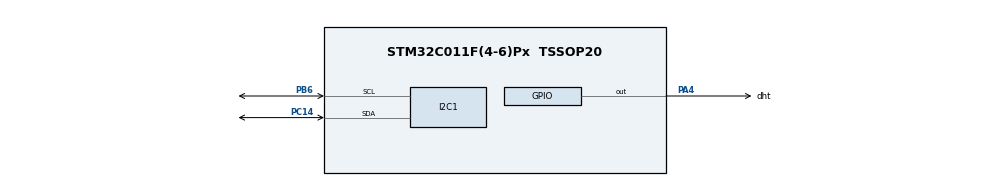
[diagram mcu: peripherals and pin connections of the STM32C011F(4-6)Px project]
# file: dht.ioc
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I2C1.Timing=0x20303E5D
Mcu.Family=STM32C0
Mcu.Name=STM32C011F(4-6)Px
Mcu.Package=TSSOP20
PA13.Mode=Serial_Wire
PA13.Signal=DEBUG_SWDIO
PA14-BOOT0.Mode=Serial_Wire
PA14-BOOT0.Signal=DEBUG_SWCLK
PA4.GPIO_Label=dht
PA4.GPIO_Speed=GPIO_SPEED_FREQ_VERY_HIGH
PA4.PinState=GPIO_PIN_SET
PA4.Signal=GPIO_Output
PB6.Mode=I2C
PB6.Signal=I2C1_SCL
PC14-OSCX_IN\ (PC14).Mode=I2C
PC14-OSCX_IN\ (PC14).Signal=I2C1_SDA
ProjectManager.HeapSize=0x200
ProjectManager.StackSize=0x400
ProjectManager.TargetToolchain=STM32CubeIDE
RCC.ADCFreq_Value=48000000
RCC.AHBFreq_Value=48000000
RCC.CortexFreq_Value=48000000
RCC.EXTERNAL_CLOCK_VALUE=12288000
RCC.HCLKFreq_Value=48000000
RCC.HSE_VALUE=8000000
RCC.HSISYSCLKDivider=RCC_HSI_DIV1
RCC.HSI_VALUE=48000000
RCC.LSE_VALUE=32768
RCC.SYSCLKFreq_VALUE=48000000
TIM3.Period=\ 65535
TIM3.Prescaler=48-1
VP_TIM3_VS_ClockSourceINT.Mode=Internal
board=custom

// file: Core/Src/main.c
/* USER CODE BEGIN Header */
/**
  ******************************************************************************
  * @file           : main.c
  * @brief          : Main program body
  ******************************************************************************
  * @attention
  *
  * Copyright (c) 2024 STMicroelectronics.
  * All rights reserved.
  *
  * This software is licensed under terms that can be found in the LICENSE file
  * in the root directory of this software component.
  * If no LICENSE file comes with this software, it is provided AS-IS.
  *
  ******************************************************************************
  */
/* USER CODE END Header */
#include "main.h"

/* USER CODE BEGIN Includes */
#include "stdio.h"
#include "string.h"
#include "ssd1306.h"
#include "ssd1306_fonts.h"
/* USER CODE END Includes */

I2C_HandleTypeDef hi2c1;

TIM_HandleTypeDef htim3;

/* USER CODE BEGIN PV */
uint16_t temperatura, umidade;
/* USER CODE END PV */

void SystemClock_Config(void);
static void MX_GPIO_Init(void);
static void MX_I2C1_Init(void);
static void MX_TIM3_Init(void);
/* USER CODE BEGIN PFP */
void dht11(uint16_t *temperatura, uint16_t *umidade);
void Display_Data(uint16_t *temperatura, uint16_t *umidade);
/* USER CODE END PFP */

/* USER CODE BEGIN 0 */

void dht11(uint16_t *temperatura, uint16_t *umidade)
{
	//Variáveis para execução de cálculos da função.
	uint16_t tempcalc, umidcalc;

	//Configurações para seleção da direção do Pino 'dht11' como saída digital:
	GPIO_InitTypeDef GPIO_InitStruct = {0};
	GPIO_InitStruct.Pin = dht_Pin;
	GPIO_InitStruct.Mode = GPIO_MODE_OUTPUT_PP;
	GPIO_InitStruct.Pull = GPIO_NOPULL;
	GPIO_InitStruct.Speed = GPIO_SPEED_FREQ_VERY_HIGH;
	HAL_GPIO_Init(dht_GPIO_Port, &GPIO_InitStruct);

	//Sinal em nivel lógico 0 - Conforme Datasheet.
	HAL_GPIO_WritePin(dht_GPIO_Port, dht_Pin, GPIO_PIN_RESET);

	//Tempo mínimo de 18ms - Conforme Datasheet.
	HAL_Delay(20); //Configura para 20ms

	//Sinal em nivel lógico 1 - Conforme Datasheet.
	HAL_GPIO_WritePin(dht_GPIO_Port, dht_Pin, GPIO_PIN_SET);

	//Configurações para seleção da direção do Pino 'dht11' como entrada digital:
	GPIO_InitStruct.Pin = dht_Pin;
	GPIO_InitStruct.Mode = GPIO_MODE_INPUT;
	GPIO_InitStruct.Pull = GPIO_NOPULL;
	GPIO_InitStruct.Speed = GPIO_SPEED_FREQ_VERY_HIGH;
	HAL_GPIO_Init(dht_GPIO_Port, &GPIO_InitStruct);

	//Lógica Principal:
	//Seta contador Timer 3 para 0.
	__HAL_TIM_SET_COUNTER(&htim3, 0);

	//Variáveis Auxiliares.
	uint16_t ler[2];
	uint16_t dados[42];
	uint8_t bits[40];
	uint16_t temph = 0;
	uint16_t umidh = 0;

	//Lógica Para Captura do Tempo Alto dos Dados.
	for(int i = 0; i < 42; i++)
	{
	    while(HAL_GPIO_ReadPin(dht_GPIO_Port, dht_Pin) == GPIO_PIN_RESET);
	    ler[0] = __HAL_TIM_GET_COUNTER(&htim3);
		while(HAL_GPIO_ReadPin(dht_GPIO_Port, dht_Pin) == GPIO_PIN_SET);
		ler[1] = __HAL_TIM_GET_COUNTER(&htim3);
		dados[i] = ler[1] - ler[0];
	}

	//Definindo bits conforme tempos do datasheet.
	for(int i = 0; i < 40; i++)
	{
	    if((dados[i+2] >=20) && (dados[i+2] <=32))
	    {
		    bits[i] = 0;
	    }
	    else if((dados[i+2] >=65) && (dados[i+2] <=75))
	    {
		    bits[i] = 1;
	    }
	}

	//Cálculo da temperatura e umidade determinado pelos bits.
	for(int i = 0; i < 8; i++)
	{
	    temph += bits[i+16] << (7 - i);
	    umidh += bits[i] << (7 - i);
	}

	//Atribuição dos valores calculados nas variáveis
	tempcalc = temph;
	umidcalc = umidh;
	*temperatura = tempcalc;
	*umidade = umidcalc;
}

void Display_Data(uint16_t *temperatura, uint16_t *umidade) {
	char temp_str[16];
	char hum_str[16];

	// Formatando as strings de temperatura e umidade manualmente
	sprintf(temp_str, "Temp: %dC", (int)*temperatura);
	sprintf(hum_str, "Umid: %d%%", (int)*umidade);

	// Limpar o display
	ssd1306_Fill(Black);

	// Definir o cursor e escrever a string de temperatura
	ssd1306_SetCursor(4, 4);
	ssd1306_WriteString(temp_str, Font_11x18, White);

	// Definir o cursor e escrever a string de umidade
	ssd1306_SetCursor(4, 24);
	ssd1306_WriteString(hum_str, Font_11x18, White);

	// Atualizar o display
	ssd1306_UpdateScreen();
}

/* USER CODE END 0 */

int main(void)
{

  /* MCU Configuration--------------------------------------------------------*/

  /* Reset of all peripherals, Initializes the Flash interface and the Systick. */
  HAL_Init();

  /* Configure the system clock */
  SystemClock_Config();

  /* Initialize all configured peripherals */
  MX_GPIO_Init();
  MX_I2C1_Init();
  MX_TIM3_Init();
  /* USER CODE BEGIN 2 */
  HAL_TIM_Base_Start(&htim3); //Inicializa Timer 3 -> '1us'
  ssd1306_Init();
  /* USER CODE END 2 */

  /* Infinite loop */
  while (1)
  {

    /* USER CODE BEGIN 3 */
	dht11(&temperatura, &umidade);
	Display_Data(&temperatura, &umidade);
	HAL_Delay(5000); // Aguarda 5 segundos antes de fazer uma nova leitura
  }
  /* USER CODE END 3 */
}

void SystemClock_Config(void)
{
  RCC_OscInitTypeDef RCC_OscInitStruct = {0};
  RCC_ClkInitTypeDef RCC_ClkInitStruct = {0};

  /** Initializes the RCC Oscillators according to the specified parameters
  * in the RCC_OscInitTypeDef structure.
  */
  RCC_OscInitStruct.OscillatorType = RCC_OSCILLATORTYPE_HSI;
  RCC_OscInitStruct.HSIState = RCC_HSI_ON;
  RCC_OscInitStruct.HSIDiv = RCC_HSI_DIV1;
  RCC_OscInitStruct.HSICalibrationValue = RCC_HSICALIBRATION_DEFAULT;
  if (HAL_RCC_OscConfig(&RCC_OscInitStruct) != HAL_OK)
  {
    Error_Handler();
  }

  /** Initializes the CPU, AHB and APB buses clocks
  */
  RCC_ClkInitStruct.ClockType = RCC_CLOCKTYPE_HCLK|RCC_CLOCKTYPE_SYSCLK
                              |RCC_CLOCKTYPE_PCLK1;
  RCC_ClkInitStruct.SYSCLKSource = RCC_SYSCLKSOURCE_HSI;
  RCC_ClkInitStruct.SYSCLKDivider = RCC_SYSCLK_DIV1;
  RCC_ClkInitStruct.AHBCLKDivider = RCC_HCLK_DIV1;
  RCC_ClkInitStruct.APB1CLKDivider = RCC_APB1_DIV1;

  if (HAL_RCC_ClockConfig(&RCC_ClkInitStruct, FLASH_LATENCY_1) != HAL_OK)
  {
    Error_Handler();
  }
}

static void MX_I2C1_Init(void)
{

  hi2c1.Instance = I2C1;
  hi2c1.Init.Timing = 0x20303E5D;
  hi2c1.Init.OwnAddress1 = 0;
  hi2c1.Init.AddressingMode = I2C_ADDRESSINGMODE_7BIT;
  hi2c1.Init.DualAddressMode = I2C_DUALADDRESS_DISABLE;
  hi2c1.Init.OwnAddress2 = 0;
  hi2c1.Init.OwnAddress2Masks = I2C_OA2_NOMASK;
  hi2c1.Init.GeneralCallMode = I2C_GENERALCALL_DISABLE;
  hi2c1.Init.NoStretchMode = I2C_NOSTRETCH_DISABLE;
  if (HAL_I2C_Init(&hi2c1) != HAL_OK)
  {
    Error_Handler();
  }

  /** Configure Analogue filter
  */
  if (HAL_I2CEx_ConfigAnalogFilter(&hi2c1, I2C_ANALOGFILTER_ENABLE) != HAL_OK)
  {
    Error_Handler();
  }

  /** Configure Digital filter
  */
  if (HAL_I2CEx_ConfigDigitalFilter(&hi2c1, 0) != HAL_OK)
  {
    Error_Handler();
  }

}

static void MX_TIM3_Init(void)
{

  TIM_ClockConfigTypeDef sClockSourceConfig = {0};
  TIM_MasterConfigTypeDef sMasterConfig = {0};

  htim3.Instance = TIM3;
  htim3.Init.Prescaler = 48-1;
  htim3.Init.CounterMode = TIM_COUNTERMODE_UP;
  htim3.Init.Period = 65535;
  htim3.Init.ClockDivision = TIM_CLOCKDIVISION_DIV1;
  htim3.Init.AutoReloadPreload = TIM_AUTORELOAD_PRELOAD_DISABLE;
  if (HAL_TIM_Base_Init(&htim3) != HAL_OK)
  {
    Error_Handler();
  }
  sClockSourceConfig.ClockSource = TIM_CLOCKSOURCE_INTERNAL;
  if (HAL_TIM_ConfigClockSource(&htim3, &sClockSourceConfig) != HAL_OK)
  {
    Error_Handler();
  }
  sMasterConfig.MasterOutputTrigger = TIM_TRGO_RESET;
  sMasterConfig.MasterSlaveMode = TIM_MASTERSLAVEMODE_DISABLE;
  if (HAL_TIMEx_MasterConfigSynchronization(&htim3, &sMasterConfig) != HAL_OK)
  {
    Error_Handler();
  }

}

static void MX_GPIO_Init(void)
{
  GPIO_InitTypeDef GPIO_InitStruct = {0};

  /* GPIO Ports Clock Enable */
  __HAL_RCC_GPIOC_CLK_ENABLE();
  __HAL_RCC_GPIOA_CLK_ENABLE();
  __HAL_RCC_GPIOB_CLK_ENABLE();

  /*Configure GPIO pin Output Level */
  HAL_GPIO_WritePin(dht_GPIO_Port, dht_Pin, GPIO_PIN_SET);

  /*Configure GPIO pin : dht_Pin */
  GPIO_InitStruct.Pin = dht_Pin;
  GPIO_InitStruct.Mode = GPIO_MODE_OUTPUT_PP;
  GPIO_InitStruct.Pull = GPIO_NOPULL;
  GPIO_InitStruct.Speed = GPIO_SPEED_FREQ_VERY_HIGH;
  HAL_GPIO_Init(dht_GPIO_Port, &GPIO_InitStruct);

}

void Error_Handler(void)
{
  __disable_irq();
  while (1)
  {
  }
}
